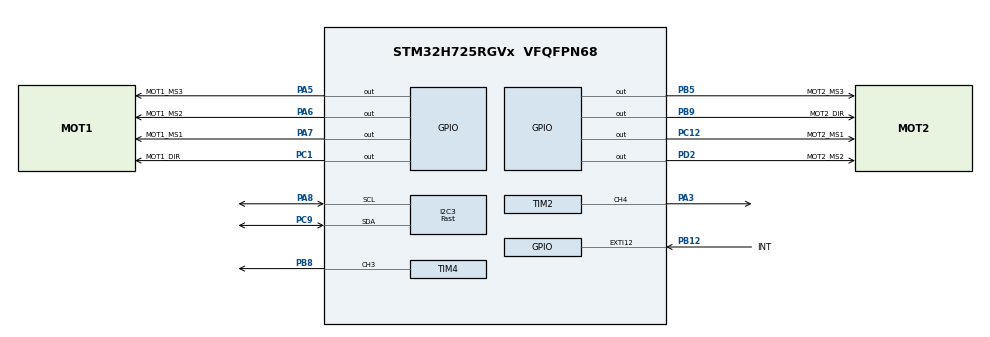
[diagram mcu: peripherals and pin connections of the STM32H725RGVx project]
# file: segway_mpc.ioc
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FREERTOS.Tasks01=defaultTask,24,1024,app_main,As weak,NULL,Static,defaultTaskBuffer,defaultTaskControlBlock
I2C3.I2C_Speed_Mode=I2C_Fast
I2C3.Speed=400
I2C3.Timing=0x00D049FB
Mcu.Family=STM32H7
Mcu.Name=STM32H725RGVx
Mcu.Package=VFQFPN68
NVIC.EXTI15_10_IRQn=true\:5\:0\:false\:false\:true\:true\:true\:true\:true
NVIC.PriorityGroup=NVIC_PRIORITYGROUP_4
NVIC.TIM1_UP_IRQn=true\:15\:0\:false\:false\:true\:false\:false\:true\:true
NVIC.TIM3_IRQn=true\:5\:0\:false\:false\:true\:true\:true\:true\:true
NVIC.TimeBase=TIM1_UP_IRQn
NVIC.TimeBaseIP=TIM1
PA3.Signal=S_TIM2_CH4
PA5.GPIO_Label=MOT1_MS3
PA5.Signal=GPIO_Output
PA6.GPIO_Label=MOT1_MS2
PA6.Signal=GPIO_Output
PA7.GPIO_Label=MOT1_MS1
PA7.Signal=GPIO_Output
PA8.GPIO_Pu=GPIO_NOPULL
PA8.Mode=I2C
PA8.Signal=I2C3_SCL
PB12.GPIO_Label=INT
PB12.Signal=GPXTI12
PB5.GPIO_Label=MOT2_MS3
PB5.Signal=GPIO_Output
PB8.Signal=S_TIM4_CH3
PB9.GPIO_Label=MOT2_DIR
PB9.Signal=GPIO_Output
PC1.GPIO_Label=MOT1_DIR
PC1.Signal=GPIO_Output
PC12.GPIO_Label=MOT2_MS1
PC12.Signal=GPIO_Output
PC9.GPIO_Pu=GPIO_NOPULL
PC9.Mode=I2C
PC9.Signal=I2C3_SDA
PD2.GPIO_Label=MOT2_MS2
PD2.Signal=GPIO_Output
ProjectManager.HeapSize=0x200
ProjectManager.StackSize=0x400
ProjectManager.TargetToolchain=CMake
RCC.ADCFreq_Value=129000000
RCC.APB1Freq_Value=137500000
RCC.APB2Freq_Value=137500000
RCC.APB3Freq_Value=137500000
RCC.APB4Freq_Value=137500000
RCC.CortexFreq_Value=550000000
RCC.D1PPRE=RCC_APB3_DIV2
RCC.D2PPRE1=RCC_APB1_DIV2
RCC.D2PPRE2=RCC_APB2_DIV2
RCC.D3PPRE=RCC_APB4_DIV2
RCC.DIVM1=4
RCC.DIVN1=34
RCC.DIVP1=1
RCC.DIVQ1=4
RCC.HCLKFreq_Value=275000000
RCC.HPRE=RCC_HCLK_DIV2
RCC.PLL2FRACN=0
RCC.PLL2_VCO_SEL-AdvancedSettings=RCC_PLL2VCOMEDIUM
RCC.PLL3FRACN=0
RCC.PLLFRACN=3072
RCC.SYSCLKFreq_VALUE=550000000
RCC.SYSCLKSource=RCC_SYSCLKSOURCE_PLLCLK
RCC.USBFreq_Value=137500000
SH.S_TIM2_CH4.0=TIM2_CH4,PWM Generation4 CH4
SH.S_TIM4_CH3.0=TIM4_CH3,PWM Generation3 CH3
TIM2.Channel-PWM\ Generation4\ CH4=TIM_CHANNEL_4
TIM2.Prescaler=63
TIM3.Period=19999
TIM3.Prescaler=274
TIM4.Channel-PWM\ Generation3\ CH3=TIM_CHANNEL_3
VP_FREERTOS_VS_CMSIS_V2.Mode=CMSIS_V2
VP_MEMORYMAP_VS_MEMORYMAP.Mode=CurAppReg
VP_SYS_VS_tim1.Mode=TIM1
VP_TIM2_VS_ClockSourceINT.Mode=Internal
VP_TIM3_VS_ClockSourceINT.Mode=Internal
VP_TIM4_VS_ClockSourceINT.Mode=Internal
board=custom

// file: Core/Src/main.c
/* USER CODE BEGIN Header */
/**
 ******************************************************************************
 * @file           : main.c
 * @brief          : Main program body
 ******************************************************************************
 * @attention
 *
 * Copyright (c) 2026 STMicroelectronics.
 * All rights reserved.
 *
 * This software is licensed under terms that can be found in the LICENSE file
 * in the root directory of this software component.
 * If no LICENSE file comes with this software, it is provided AS-IS.
 *
 ******************************************************************************
 */
/* USER CODE END Header */
#include "main.h"
#include "cmsis_os.h"
#include "i2c.h"
#include "memorymap.h"
#include "tim.h"
#include "gpio.h"

/* USER CODE BEGIN Includes */
#include "logger/logger.h"
#include "mpc_task/mpc_task.h"
#include "step_motor/step_manager.h"
/* USER CODE END Includes */

void SystemClock_Config(void);
void MX_FREERTOS_Init(void);

int main(void)
{

  /* MCU Configuration--------------------------------------------------------*/

  /* Reset of all peripherals, Initializes the Flash interface and the Systick. */
  HAL_Init();

  /* Configure the system clock */
  SystemClock_Config();

  /* Initialize all configured peripherals */
  MX_GPIO_Init();
  MX_I2C3_Init();
  MX_TIM2_Init();
  MX_TIM4_Init();
  MX_TIM3_Init();
  /* USER CODE BEGIN 2 */
    // HAL_TIM_IC_Start_IT(&htim2, TIM_CHANNEL_1);
    // HAL_TIM_IC_Start_IT(&htim2, TIM_CHANNEL_2);
    // HAL_TIM_IC_Start_IT(&htim2, TIM_CHANNEL_3);
    // HAL_TIM_IC_Start_IT(&htim2, TIM_CHANNEL_4);
  /* USER CODE END 2 */

  /* Init scheduler */
  osKernelInitialize();

  /* Call init function for freertos objects (in cmsis_os2.c) */
  MX_FREERTOS_Init();

  /* Start scheduler */
  osKernelStart();

  /* We should never get here as control is now taken by the scheduler */

  /* Infinite loop */
    while (1) {

    }
}

void SystemClock_Config(void)
{
  RCC_OscInitTypeDef RCC_OscInitStruct = {0};
  RCC_ClkInitTypeDef RCC_ClkInitStruct = {0};

  /** Supply configuration update enable
  */
  HAL_PWREx_ConfigSupply(PWR_DIRECT_SMPS_SUPPLY);

  /** Configure the main internal regulator output voltage
  */
  __HAL_PWR_VOLTAGESCALING_CONFIG(PWR_REGULATOR_VOLTAGE_SCALE0);

  while(!__HAL_PWR_GET_FLAG(PWR_FLAG_VOSRDY)) {}

  /** Initializes the RCC Oscillators according to the specified parameters
  * in the RCC_OscInitTypeDef structure.
  */
  RCC_OscInitStruct.OscillatorType = RCC_OSCILLATORTYPE_HSI;
  RCC_OscInitStruct.HSIState = RCC_HSI_DIV1;
  RCC_OscInitStruct.HSICalibrationValue = 64;
  RCC_OscInitStruct.PLL.PLLState = RCC_PLL_ON;
  RCC_OscInitStruct.PLL.PLLSource = RCC_PLLSOURCE_HSI;
  RCC_OscInitStruct.PLL.PLLM = 4;
  RCC_OscInitStruct.PLL.PLLN = 34;
  RCC_OscInitStruct.PLL.PLLP = 1;
  RCC_OscInitStruct.PLL.PLLQ = 4;
  RCC_OscInitStruct.PLL.PLLR = 2;
  RCC_OscInitStruct.PLL.PLLRGE = RCC_PLL1VCIRANGE_3;
  RCC_OscInitStruct.PLL.PLLVCOSEL = RCC_PLL1VCOWIDE;
  RCC_OscInitStruct.PLL.PLLFRACN = 3072;
  if (HAL_RCC_OscConfig(&RCC_OscInitStruct) != HAL_OK)
  {
    Error_Handler();
  }

  /** Initializes the CPU, AHB and APB buses clocks
  */
  RCC_ClkInitStruct.ClockType = RCC_CLOCKTYPE_HCLK|RCC_CLOCKTYPE_SYSCLK
                              |RCC_CLOCKTYPE_PCLK1|RCC_CLOCKTYPE_PCLK2
                              |RCC_CLOCKTYPE_D3PCLK1|RCC_CLOCKTYPE_D1PCLK1;
  RCC_ClkInitStruct.SYSCLKSource = RCC_SYSCLKSOURCE_PLLCLK;
  RCC_ClkInitStruct.SYSCLKDivider = RCC_SYSCLK_DIV1;
  RCC_ClkInitStruct.AHBCLKDivider = RCC_HCLK_DIV2;
  RCC_ClkInitStruct.APB3CLKDivider = RCC_APB3_DIV2;
  RCC_ClkInitStruct.APB1CLKDivider = RCC_APB1_DIV2;
  RCC_ClkInitStruct.APB2CLKDivider = RCC_APB2_DIV2;
  RCC_ClkInitStruct.APB4CLKDivider = RCC_APB4_DIV2;

  if (HAL_RCC_ClockConfig(&RCC_ClkInitStruct, FLASH_LATENCY_3) != HAL_OK)
  {
    Error_Handler();
  }
}

void HAL_TIM_PeriodElapsedCallback(TIM_HandleTypeDef *htim)
{
  /* USER CODE BEGIN Callback 0 */
    if (htim->Instance == TIM3) {
        mpc_wake_up();
    }
  /* USER CODE END Callback 0 */
  if (htim->Instance == TIM1)
  {
    HAL_IncTick();
  }
}

void Error_Handler(void)
{
    __disable_irq();
    while (1) {
    }
}

#ifdef  USE_FULL_ASSERT
/**
  * @brief  Reports the name of the source file and the source line number
  *         where the assert_param error has occurred.
  * @param  file: pointer to the source file name
  * @param  line: assert_param error line source number
  * @retval None
  */
void assert_failed(uint8_t *file, uint32_t line)
{
  /* USER CODE BEGIN 6 */
    LOG_ERROR("Wrong parameters value: file %s on line %d\r\n", file, line);
    while (1) {
    }
    /* User can add his own implementation to report the file name and line number,
       ex: printf("Wrong parameters value: file %s on line %d\r\n", file, line) */
  /* USER CODE END 6 */
}
#endif /* USE_FULL_ASSERT */

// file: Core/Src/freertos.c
/* USER CODE BEGIN Header */
/**
  ******************************************************************************
  * File Name          : freertos.c
  * Description        : Code for freertos applications
  ******************************************************************************
  * @attention
  *
  * Copyright (c) 2026 STMicroelectronics.
  * All rights reserved.
  *
  * This software is licensed under terms that can be found in the LICENSE file
  * in the root directory of this software component.
  * If no LICENSE file comes with this software, it is provided AS-IS.
  *
  ******************************************************************************
  */
/* USER CODE END Header */

#include "FreeRTOS.h"
#include "task.h"
#include "main.h"
#include "cmsis_os.h"

typedef StaticTask_t osStaticThreadDef_t;

/* Definitions for defaultTask */
osThreadId_t defaultTaskHandle;
uint32_t defaultTaskBuffer[ 1024 ];
osStaticThreadDef_t defaultTaskControlBlock;
const osThreadAttr_t defaultTask_attributes = {
  .name = "defaultTask",
  .cb_mem = &defaultTaskControlBlock,
  .cb_size = sizeof(defaultTaskControlBlock),
  .stack_mem = &defaultTaskBuffer[0],
  .stack_size = sizeof(defaultTaskBuffer),
  .priority = (osPriority_t) osPriorityNormal,
};

void app_main(void *argument);

void MX_FREERTOS_Init(void); /* (MISRA C 2004 rule 8.1) */

void MX_FREERTOS_Init(void) {

  /* Create the thread(s) */
  /* creation of defaultTask */
  defaultTaskHandle = osThreadNew(app_main, NULL, &defaultTask_attributes);

}

__weak void app_main(void *argument)
{
  for(;;)
  {
    osDelay(1);
  }
}
